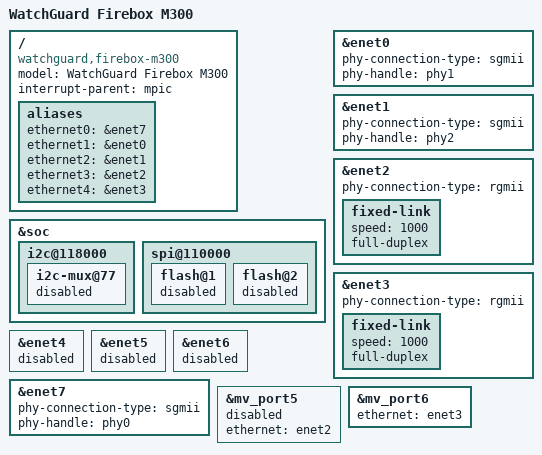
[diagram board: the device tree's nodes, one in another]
// SPDX-License-Identifier: BSD-3-Clause OR GPL-2.0-or-later
/*
 * WatchGuard Firebox M300 Device Tree Source
 * Based on t2081qds.dts from Linux 5.10
 *
 * Copyright 2013 - 2015 Freescale Semiconductor Inc.
 * Copyright 2020 - 2021 Stijn Tintel <stijn@linux-ipv6.be>
 */

#include <dt-bindings/gpio/gpio.h>
#include <dt-bindings/input/input.h>

/include/ "t208xsi-pre.dtsi"
/include/ "t208xqds.dtsi"

/ {
	model = "WatchGuard Firebox M300";
	compatible = "watchguard,firebox-m300", "fsl,T2081QDS";

	interrupt-parent = <&mpic>;

	aliases {
		/delete-property/ ethernet0;
		/delete-property/ ethernet1;
		/delete-property/ ethernet2;
		/delete-property/ ethernet3;
		/delete-property/ ethernet4;
		/delete-property/ ethernet5;
		/delete-property/ ethernet6;
		/delete-property/ ethernet7;

		ethernet0 = &enet7;
		ethernet1 = &enet0;
		ethernet2 = &enet1;
		ethernet3 = &enet2;
		ethernet4 = &enet3;
	};
};

&soc {
// Include first to make this the first interface
/include/ "qoriq-fman3-0-10g-1.dtsi"
};

// mdio-mux under &boardctrl + its aliases removed. causes crash:
// Oops: Machine check, sig: 7 [#1]

/include/ "t2081si-post.dtsi"

// add stuff below the include to make sure we override whatever is there

#include "watchguard-firebox-mx00.dtsi"

&enet0 {
	phy-connection-type = "sgmii";
	phy-handle = <&phy1>;
};

&enet1 {
	phy-connection-type = "sgmii";
	phy-handle = <&phy2>;
};

&enet2 {
	phy-connection-type = "rgmii";

	fixed-link {
		speed = <1000>;
		full-duplex;
	};
};

&enet3 {
	phy-connection-type = "rgmii";

	fixed-link {
		speed = <1000>;
		full-duplex;
	};
};

&enet4 {
	status = "disabled";
};

&enet5 {
	status = "disabled";
};

&enet6 {
	status = "disabled";
};

&enet7 {
	phy-connection-type = "sgmii";
	phy-handle = <&phy0>;
};

// The OEM driver uses both CPU ports in split mode. Keep the
// second link disabled until multi-CPU-port operation is supported.
&mv_port5 {
	status = "disabled";
	ethernet = <&enet2>;
};

&mv_port6 {
	ethernet = <&enet3>;
};

&soc {
	i2c@118000 {
		i2c-mux@77 {
				status = "disabled";
		};
	};

	spi@110000 {
			flash@1 {
					status = "disabled";
			};

			flash@2 {
					status = "disabled";
			};
	};
};
